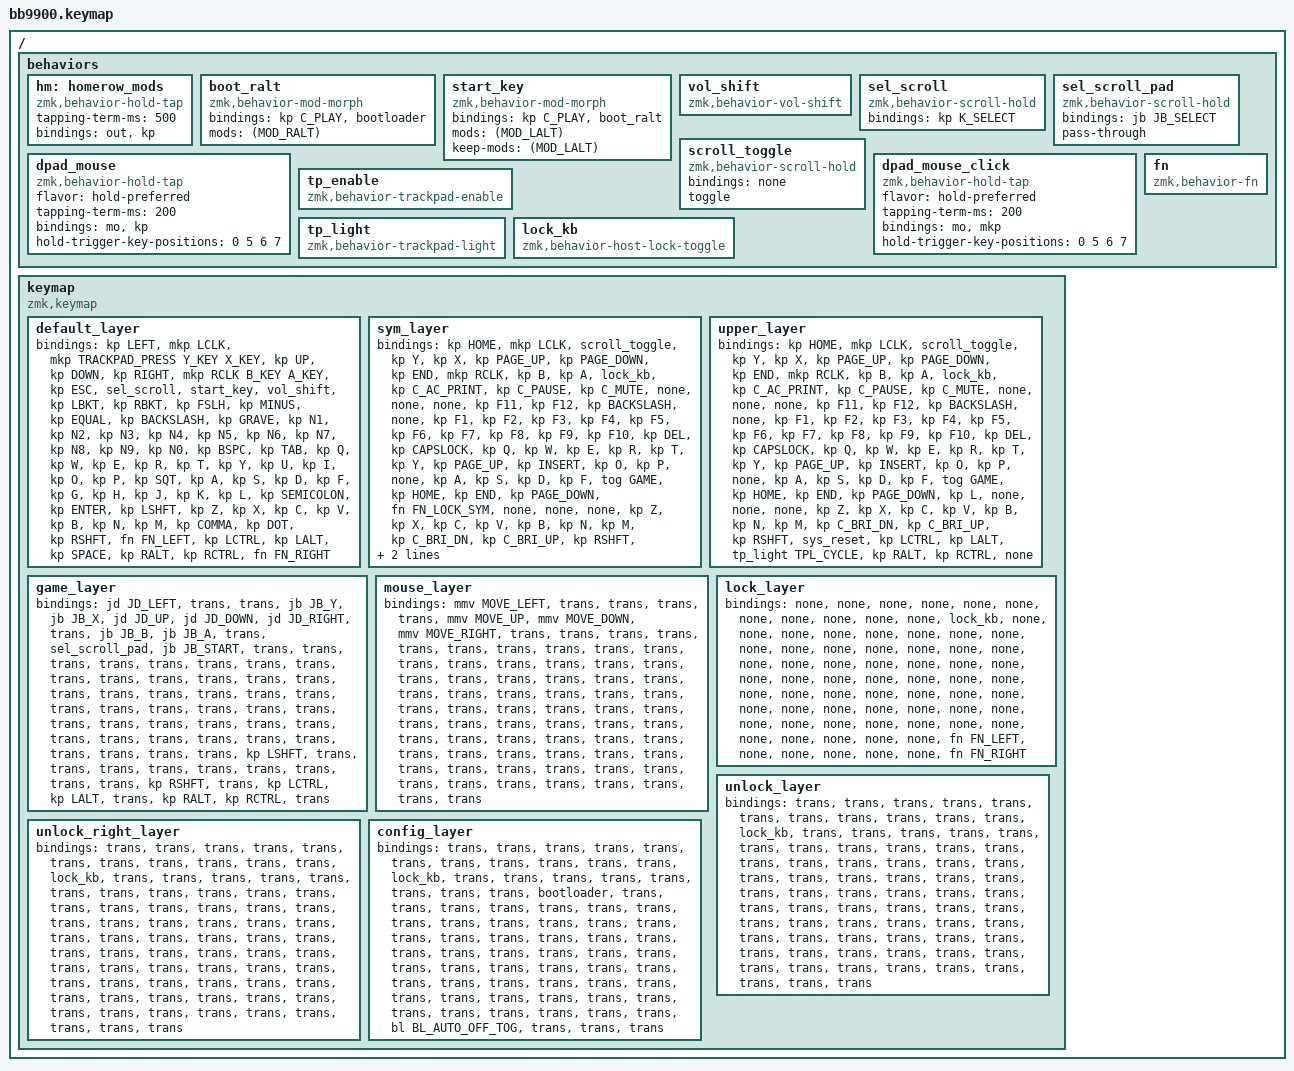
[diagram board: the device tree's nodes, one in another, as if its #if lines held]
/*
 * Copyright (c) 2023 ZitaoTech
 *
 * SPDX-License-Identifier: MIT
 */
   
#include <behaviors.dtsi>
#include <dt-bindings/zmk/keys.h>
#include <dt-bindings/zmk/bt.h>
#include <dt-bindings/zmk/outputs.h>
#include <dt-bindings/zmk/mouse.h>
#include <dt-bindings/zmk/backlight.h>
#include <dt-bindings/zmk/ext_power.h>
#include <dt-bindings/zmk/modifiers.h>
#include <dt-bindings/zmk/joystick.h>
#include <dt-bindings/zmk/trackpad.h>

#define SYM 1
#define UPPER 2
// GAME is gamepad mode, toggled with Fn+G. It sits at index 3 on purpose:
// the layer LED code in the ZMK fork blinks for layer 3.
#define GAME 3
// Held Y or B: the D-pad moves the pointer.
#define MOUSE 4
// Keyboard lock, toggled with Fn+Esc. LOCK swallows every key; the separate
// unlock layers keep either Fn's Esc route alive when both Fn keys are held.
#define LOCK 5
#define UNLOCK_LEFT 6
// Right Fn reaches its own unlock layer while locked.
#define UNLOCK_RIGHT 7
// Second way into the bootloader, a fallback that relies on nothing but
// plain layers: hold Left Fn, then also hold Right Fn, then press the \ key.
#define CONFIG 8
#define FN_LEFT 0
#define FN_RIGHT 1
#define FN_LOCK_SYM 2

// Two mouse buttons that come as a pair: what pressing the trackpad does, and
// what a tap on the B button does. Each is LCLK (left), MCLK (middle) or RCLK
// (right). The standard firmware has left click on the trackpad and middle
// click on B. The middle-click firmware in build.yaml swaps them by defining
// MIDDLE_CLICK_TRACKPAD from the command line. For your own build, change the
// two values after the #else.
#ifdef MIDDLE_CLICK_TRACKPAD
#define TRACKPAD_PRESS MCLK
#else
#define TRACKPAD_PRESS LCLK
#endif

// The four face buttons in keyboard mode (default_layer). The one-handed
// firmware in build.yaml defines ONE_HANDED from the command line, which puts
// the mouse buttons and a scroll switch on them for right-hand use, at the
// cost of the D-pad pointer (Y, B) and the kitty key (A). For your own build,
// change the four values after the #else.
#ifdef ONE_HANDED
#define Y_KEY &mkp MCLK
#define X_KEY &scroll_toggle
#define B_KEY &mkp RCLK
#define A_KEY &kp F11
#else
#define Y_KEY &dpad_mouse MOUSE F21
#define X_KEY &kp F22
#define B_KEY &dpad_mouse MOUSE F23
#define A_KEY &kp F24
#endif

// Ctrl+Shift+<key>, the kitty_mod chord. Used throughout the KITTY layer.
#define KM(k) &kp LC(LS(k))

// Joystick button numbers in gamepad mode, as on the uConsole QMK firmware.
#define JB_A 0
#define JB_B 1
#define JB_X 2
#define JB_Y 3
#define JB_SELECT 4
#define JB_START 5


/ {
    behaviors {
        hm: homerow_mods {
            compatible = "zmk,behavior-hold-tap";
            #binding-cells = <2>;
            tapping-term-ms = <500>;
            bindings = <&out &kp>;
        };
    };

    // Bootloader shortcut: Left Alt + Right Alt + Start, as on the uConsole
    // QMK firmware. The Start key is Super unless both Alt keys are down.
    //
    // A ZMK mod-morph fires when ANY of its listed modifiers is held, not all
    // of them, so one morph listing both Alts would fire on either. Two
    // morphs nested, one modifier each, give a real AND:
    //
    //   start_key: no Left Alt  -> Start
    //              Left Alt     -> boot_ralt, with Left Alt left in place
    //   boot_ralt: no Right Alt -> Start (so Left Alt + Start is Alt+Super)
    //              Right Alt    -> &bootloader
    //
    // The Alt keys are one-shot, and a tapped ("armed") one-shot counts as
    // held. So tapping both Alts and then Start also gets here. An earlier
    // Ctrl+Alt+\ shortcut was dropped for exactly that reason: an armed Ctrl
    // followed by an ordinary Alt+\ was far too easy to produce.
    //
    // The fallback, which no one-shot can trigger, is in config_layer: hold
    // Left Fn, then also Right Fn, then press the \ key.
    //
    // This is a mod-morph rather than a ZMK `combos` block because thoughtfix
    // found that any combos block on this board stopped the Enter key working.
    behaviors {
        boot_ralt: boot_ralt {
            compatible = "zmk,behavior-mod-morph";
            #binding-cells = <0>;
            bindings = <&kp C_PLAY>, <&bootloader>;
            mods = <(MOD_RALT)>;
        };
        start_key: start_key {
            compatible = "zmk,behavior-mod-morph";
            #binding-cells = <0>;
            bindings = <&kp C_PLAY>, <&boot_ralt>;
            mods = <(MOD_LALT)>;
            keep-mods = <(MOD_LALT)>;
        };
    };

    // Volume/Mute fix (see NOTES.md): Speaker key alone = Volume Down,
    // Shift+Speaker = Volume Up, matching ClusterM's factory-spec
    // do_the_key() behavior. Both Fn layers separately rebound to Mute.
    // A plain mod-morph can't do this correctly on its own: Consumer-page
    // reports have no modifier byte, so Shift stays reported as held the
    // whole time and breaks strict WM keybind matching. vol_shift is a
    // custom behavior (zmk fork, src/behaviors/behavior_vol_shift.c) that
    // explicitly releases and restores the Shift bit around the press.
    behaviors {
        vol_shift: vol_shift {
            compatible = "zmk,behavior-vol-shift";
            #binding-cells = <0>;
        };
    };


    // Select: hold and move the trackpad to scroll; a tap with no trackpad
    // movement sends the Select key, as on the uConsole QMK firmware.
    // zmk,behavior-scroll-hold lives in the ZMK fork
    // (src/behaviors/behavior_scroll_hold.c).
    behaviors {
        sel_scroll: sel_scroll {
            compatible = "zmk,behavior-scroll-hold";
            #binding-cells = <0>;
            bindings = <&kp K_SELECT>;
        };
        // Same key in gamepad mode: the joystick Select button, down and up
        // with the key so it responds on press and can be held (pass-through),
        // and still hold-to-scroll.
        sel_scroll_pad: sel_scroll_pad {
            compatible = "zmk,behavior-scroll-hold";
            #binding-cells = <0>;
            bindings = <&jb JB_SELECT>;
            pass-through;
        };
        // A scroll switch: each press turns trackpad scrolling on or off, as
        // on the stock firmware. Only the one-handed firmware uses it, on X.
        // To have one elsewhere, put &scroll_toggle on a key, for example set
        // X_KEY to it. Hold-Select scrolling keeps working alongside it.
        scroll_toggle: scroll_toggle {
            compatible = "zmk,behavior-scroll-hold";
            #binding-cells = <0>;
            bindings = <&none>;
            toggle;
        };
    };


    // Y and B in keyboard mode, as on the uConsole QMK firmware: hold either
    // and the D-pad moves the pointer. A quick tap on its own sends a key
    // (dpad_mouse, on Y) or clicks a mouse button (dpad_mouse_click, on B).
    // Only the D-pad positions (0 5 6 7) turn a press into a hold, so rolling
    // onto any other key keeps it a tap.
    //
    // The click is sent when B is released, and only for a tap shorter than
    // tapping-term-ms, so it cannot be held down to drag. For a button that
    // can, bind the key to plain &mkp instead, which gives up its D-pad hold.
    behaviors {
        dpad_mouse: dpad_mouse {
            compatible = "zmk,behavior-hold-tap";
            #binding-cells = <2>;
            flavor = "hold-preferred";
            tapping-term-ms = <200>;
            bindings = <&mo>, <&kp>;
            hold-trigger-key-positions = <0 5 6 7>;
        };
        dpad_mouse_click: dpad_mouse_click {
            compatible = "zmk,behavior-hold-tap";
            #binding-cells = <2>;
            flavor = "hold-preferred";
            tapping-term-ms = <200>;
            bindings = <&mo>, <&mkp>;
            hold-trigger-key-positions = <0 5 6 7>;
        };
    };

    // Fn+Esc toggles the keyboard lock. The default-layer Esc remains a plain
    // Escape; this behavior is bound only where an Fn key is held or in LOCK.
    // Nothing is sent to the host either way. An earlier version also sent
    // the screen lock key, but no desktop binding for it proved reliable on
    // the uConsole, so the lock leaves the screen alone.
    // tp_enable and BL_SUSPEND / BL_RESUME come from the ZMK fork. Neither is
    // saved, and suspend leaves the backlight's own on/off state untouched,
    // which is how the previous state comes back.
    behaviors {
        tp_enable: tp_enable {
            compatible = "zmk,behavior-trackpad-enable";
            #binding-cells = <1>;
        };
    };
    // The trackpad light: Fn + / switches it off or on, and the choice is
    // saved. The lock behavior holds it off while locked without touching that
    // choice. zmk,behavior-trackpad-light lives in the ZMK fork.
    behaviors {
        tp_light: tp_light {
            compatible = "zmk,behavior-trackpad-light";
            #binding-cells = <1>;
        };
    };
    behaviors {
        lock_kb: lock_kb {
            compatible = "zmk,behavior-host-lock-toggle";
            #binding-cells = <0>;
        };
    };
    // Fn actions track physical presses separately from momentary and latched
    // layers, so Fn Lock does not make an idle Fn appear physically held.
    behaviors {
        fn: fn {
            compatible = "zmk,behavior-fn";
            #binding-cells = <1>;
        };
    };

    keymap {
        compatible = "zmk,keymap";

        default_layer {

            bindings = <
//---------------------------------------------------------------------------------------------------------
// |  ←  | ↑   | ↓   | →   |  Mleft  |  Mright |  Trackpad    |  Y  |  B  |  X  |  A  |                                       
// |  ESC   |  SELECT  | Start |                 voive  |   [  |  ]  |   /  |  -  |  =  |  \  |
// |   ~   |  1  |  2  |  3  |  4  |  5  |  6  |  7  |  8  |  9  |  0  |  Backspace  |
// |   TAB   |  Q  |  W  |  E  |  R  |  T  |  Y  |  U  |  I  |  O  |  P  | 
// |    '      |  A  |  S  |  D  |  F  |  G  |  H  |  J  |  K  |  L  |  ;  |     ENTER   |  
// |  LShift  |  Z  |  X  |  C  |  V  |  B  |  N  |  M  |  <  |  >  |  ;  |  RShift  |  
//        |  Fn  |  LCtrl  |  Alt   |      SPACE      |   Alt   |  RCtrl   |  Fn   |  
//        -----------------------------------------------------------------------------------------------------------------
            &kp LEFT                      &mkp LCLK         &mkp TRACKPAD_PRESS  Y_KEY   X_KEY
&kp UP   &kp DOWN &kp RIGHT               &mkp RCLK                       B_KEY  A_KEY
&kp ESC    &sel_scroll  &start_key &vol_shift    &kp LBKT   &kp RBKT   &kp FSLH   &kp MINUS  &kp  EQUAL &kp BACKSLASH
&kp GRAVE  &kp N1        &kp N2     &kp N3   &kp N4     &kp N5     &kp N6     &kp N7     &kp N8    &kp N9  &kp N0 &kp BSPC
&kp TAB     &kp Q         &kp W      &kp E    &kp R      &kp T      &kp Y      &kp U      &kp I     &kp O   &kp P
&kp SQT     &kp A         &kp S      &kp D    &kp F      &kp G      &kp H      &kp J      &kp K     &kp L   &kp SEMICOLON &kp ENTER        
&kp LSHFT  &kp Z         &kp X      &kp C    &kp V      &kp B      &kp N      &kp M      &kp COMMA &kp DOT &kp RSHFT
  &fn FN_LEFT &kp LCTRL &kp LALT &kp SPACE &kp RALT &kp RCTRL &fn FN_RIGHT
            >;
        };


        // Hold Left Fn and press L to toggle SYM Fn Lock. When SYM is latched,
        // L remains a normal letter unless Left Fn is physically held.
        sym_layer {

            bindings = <
        &kp HOME                      &mkp LCLK         &scroll_toggle  &kp Y   &kp X
&kp PAGE_UP   &kp PAGE_DOWN &kp END     &mkp RCLK                       &kp  B      &kp A
&lock_kb &kp C_AC_PRINT &kp C_PAUSE  &kp C_MUTE &none   &none   &none   &kp F11    &kp F12   &kp BACKSLASH
&none    &kp F1         &kp F2        &kp F3     &kp F4     &kp F5     &kp F6     &kp F7     &kp F8    &kp F9  &kp F10 &kp DEL
&kp CAPSLOCK    &kp Q          &kp W         &kp E      &kp R      &kp T      &kp Y      &kp PAGE_UP      &kp INSERT     &kp O   &kp P
&none    &kp A          &kp S         &kp D      &kp F      &tog GAME  &kp HOME      &kp END      &kp PAGE_DOWN     &fn FN_LOCK_SYM   &none &none
&none    &kp Z          &kp X         &kp C      &kp V      &kp B      &kp N      &kp M      &kp C_BRI_DN &kp C_BRI_UP &kp RSHFT
  &fn FN_LEFT &kp LCTRL &kp LGUI &bl BL_CYCLE &kp RALT &kp RCTRL &fn FN_RIGHT

            >;
        };


        upper_layer {

            bindings = <
        &kp HOME                      &mkp LCLK         &scroll_toggle  &kp Y   &kp X
&kp PAGE_UP   &kp PAGE_DOWN &kp END     &mkp RCLK                       &kp  B      &kp A
&lock_kb &kp C_AC_PRINT &kp C_PAUSE  &kp C_MUTE &none   &none   &none   &kp F11    &kp F12   &kp BACKSLASH
&none     &kp F1         &kp F2        &kp F3     &kp F4     &kp F5     &kp F6     &kp F7     &kp F8    &kp F9  &kp F10 &kp DEL
&kp CAPSLOCK    &kp Q          &kp W         &kp E      &kp R      &kp T      &kp Y      &kp PAGE_UP      &kp INSERT     &kp O   &kp P
&none    &kp A          &kp S         &kp D      &kp F      &tog GAME  &kp HOME      &kp END      &kp PAGE_DOWN     &kp L   &none &none         
&none    &kp Z          &kp X         &kp C      &kp V      &kp B      &kp N      &kp M      &kp C_BRI_DN &kp C_BRI_UP &kp RSHFT
  &sys_reset  &kp LCTRL               &kp LALT             &tp_light TPL_CYCLE           &kp RALT         &kp RCTRL     &none           

            >;
        };


        // Gamepad mode, toggled with Fn+G. The D-pad drives the joystick X/Y
        // axes, A/B/X/Y/Select/Start are joystick buttons 1-6, and modifiers
        // are plain (not one-shot). Everything else falls through, so the
        // rest of the keyboard, the trackpad and the Fn layers still work.
        // Needs CONFIG_ZMK_JOYSTICK=y (bb9900.conf).
        game_layer {

            bindings = <
            &jd JD_LEFT                   &trans            &trans     &jb JB_Y  &jb JB_X
&jd JD_UP  &jd JD_DOWN  &jd JD_RIGHT      &trans                          &jb JB_B      &jb JB_A
&trans &sel_scroll_pad &jb JB_START &trans &trans &trans &trans &trans &trans &trans
&trans &trans &trans &trans &trans &trans &trans &trans &trans &trans &trans &trans
&trans &trans &trans &trans &trans &trans &trans &trans &trans &trans &trans
&trans &trans &trans &trans &trans &trans &trans &trans &trans &trans &trans &trans
&kp LSHFT &trans &trans &trans &trans &trans &trans &trans &trans &trans &kp RSHFT
  &trans &kp LCTRL &kp LALT &trans &kp RALT &kp RCTRL &trans
            >;
        };


        // Active while Y or B is held: the D-pad moves the pointer.
        mouse_layer {

            bindings = <
            &mmv MOVE_LEFT                &trans            &trans     &trans    &trans
&mmv MOVE_UP  &mmv MOVE_DOWN  &mmv MOVE_RIGHT  &trans                     &trans        &trans
&trans &trans &trans &trans &trans &trans &trans &trans &trans &trans
&trans &trans &trans &trans &trans &trans &trans &trans &trans &trans &trans &trans
&trans &trans &trans &trans &trans &trans &trans &trans &trans &trans &trans
&trans &trans &trans &trans &trans &trans &trans &trans &trans &trans &trans &trans
&trans &trans &trans &trans &trans &trans &trans &trans &trans &trans &trans
  &trans &trans &trans &trans &trans &trans &trans
            >;
        };


        // Keyboard lock (Fn+Esc), as on the uConsole QMK firmware: every key
        // and both mouse buttons are ignored until Fn+Esc is pressed again.
        // Locking also switches the trackpad off and turns the key backlight
        // off; unlocking undoes both. LOCK is above the game and mouse layers.
        // CONFIG (layer 8) is higher, so if it was already active when LOCK is
        // engaged, its bindings keep priority until its Fn keys are released.
        // Not saved: a power cycle starts unlocked.
        lock_layer {

            bindings = <
            &none                         &none             &none      &none     &none
&none    &none    &none                   &none                           &none         &none
&lock_kb &none &none &none &none &none &none &none &none &none
&none &none &none &none &none &none &none &none &none &none &none &none
&none &none &none &none &none &none &none &none &none &none &none
&none &none &none &none &none &none &none &none &none &none &none &none
&none &none &none &none &none &none &none &none &none &none &none
  &fn FN_LEFT &none &none &none &none &none &fn FN_RIGHT
            >;
        };


        // Reached by holding Left Fn while locked. Esc toggles the lock;
        // everything else falls through to the lock layer and stays ignored.
        unlock_layer {

            bindings = <
            &trans                        &trans            &trans     &trans    &trans
&trans   &trans   &trans                  &trans                          &trans        &trans
&lock_kb &trans &trans &trans &trans &trans &trans &trans &trans &trans
&trans &trans &trans &trans &trans &trans &trans &trans &trans &trans &trans &trans
&trans &trans &trans &trans &trans &trans &trans &trans &trans &trans &trans
&trans &trans &trans &trans &trans &trans &trans &trans &trans &trans &trans &trans
&trans &trans &trans &trans &trans &trans &trans &trans &trans &trans &trans
  &trans &trans &trans &trans &trans &trans &trans
            >;
        };

        // Right Fn held while locked: this independent layer sits above LOCK,
        // preserving its Esc route when both Fn keys are down.
        unlock_right_layer {

            bindings = <
            &trans                        &trans            &trans     &trans    &trans
&trans   &trans   &trans                  &trans                          &trans        &trans
&lock_kb &trans &trans &trans &trans &trans &trans &trans &trans &trans
&trans &trans &trans &trans &trans &trans &trans &trans &trans &trans &trans &trans
&trans &trans &trans &trans &trans &trans &trans &trans &trans &trans &trans
&trans &trans &trans &trans &trans &trans &trans &trans &trans &trans &trans &trans
&trans &trans &trans &trans &trans &trans &trans &trans &trans &trans &trans
  &trans &trans &trans &trans &trans &trans &trans
            >;
        };

        // Left Fn held, then Right Fn as well: the CONFIG layer sits on top of the
        // left Fn layer. Esc toggles LOCK, \ enters the bootloader, and Space
        // toggles backlight auto-off only while unlocked. The bootloader chord
        // remains available while locked. This is a deliberate three-key,
        // two-handed chord. Fn keys are not one-shot, so unlike
        // the Alt+Alt+Start shortcut it cannot be armed by earlier taps.
        // Cannot be newly activated while locked. If already active, it stays
        // above LOCK until the held Fn keys are released.
        config_layer {

            bindings = <
            &trans                        &trans            &trans     &trans    &trans
&trans   &trans   &trans                  &trans                          &trans        &trans
&lock_kb &trans &trans &trans &trans &trans &trans &trans &trans &bootloader
&trans &trans &trans &trans &trans &trans &trans &trans &trans &trans &trans &trans
&trans &trans &trans &trans &trans &trans &trans &trans &trans &trans &trans
&trans &trans &trans &trans &trans &trans &trans &trans &trans &trans &trans &trans
&trans &trans &trans &trans &trans &trans &trans &trans &trans &trans &trans
  &trans &trans &trans &bl BL_AUTO_OFF_TOG &trans &trans &trans
            >;
        };

    };
};

